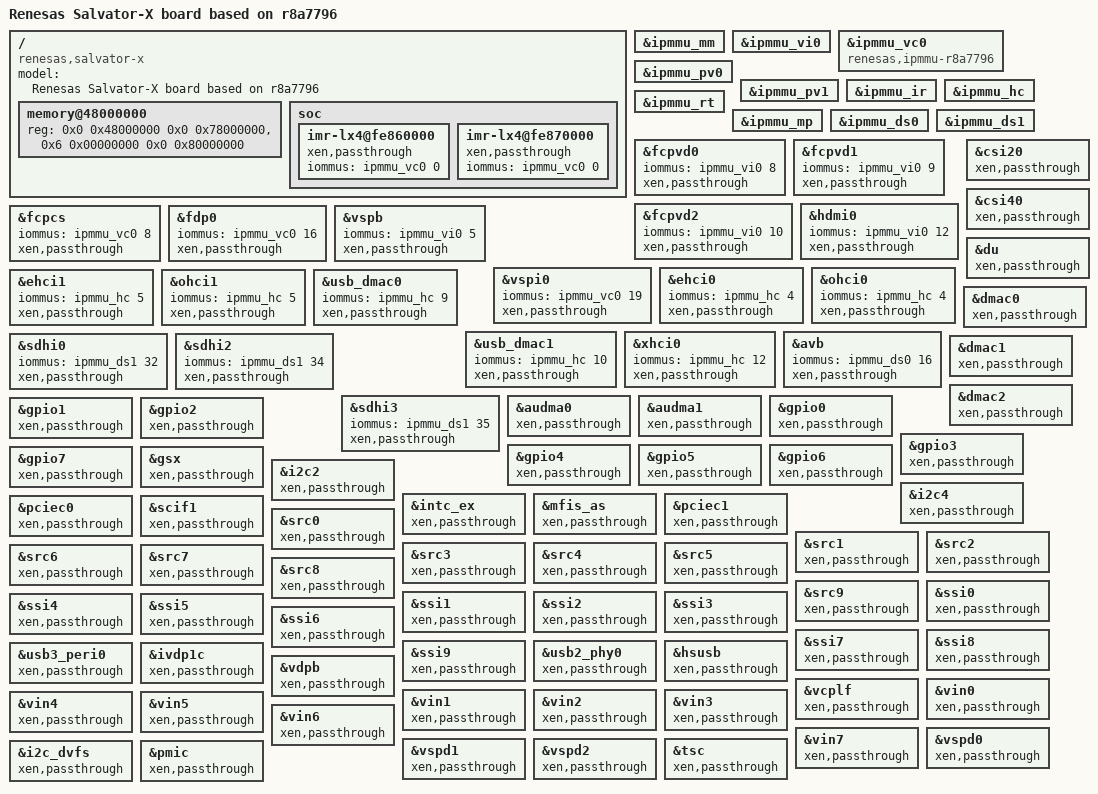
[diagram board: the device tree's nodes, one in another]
/*
 * Device Tree Source for the Salvator-X board
 *
 * Copyright (C) 2016 Renesas Electronics Corp.
 *
 * This file is licensed under the terms of the GNU General Public License
 * version 2.  This program is licensed "as is" without any warranty of any
 * kind, whether express or implied.
 */

#include "r8a7796-salvator-x.dts"
#include "xen-chosen.dtsi"

/ {
	model = "Renesas Salvator-X board based on r8a7796";
	compatible = "renesas,salvator-x", "renesas,r8a7796";

	memory@48000000 {
		device_type = "memory";
		/* first 128MB is reserved for secure area. */
		reg = <0x0 0x48000000 0x0 0x78000000>,
		      <0x6 0x00000000 0x0 0x80000000>;
	};

	/delete-node/memory@600000000;
	/delete-node/reserved-memory;

	/delete-node/mmngr;
	/delete-node/mmngrbuf;

	/*
	 * When creating DT for the guest domain Xen inserts only dummy CPU nodes.
	 * And the number of these inserted CPU nodes is equal to the number of
	 * vCPUs assigned to this domain. All CPU properties which original DT has,
	 * such as OPP, clock, regulator, etc are not passed to the guest’s DT.
	 *
	 * Example of guest vCPU node:
	 *
	 * cpu@0 {
	 *     device_type = "cpu";
	 *     compatible = "arm,armv8";
	 *     enable-method = "psci";
	 *     reg = <0x0>;
	 * };
	 *
	 * This results in the fact that all features expecting a57_x or a53_x
	 * CPU nodes to be present get broken. This is why we have to explicitly
	 * remove the following.
	 */
	/delete-node/thermal-zones;
	/delete-node/pmu_a57;
	/delete-node/pmu_a53;
};

/delete-node/&adsp;


/* ============================ Enabled IPMMUs ===============================*/
&ipmmu_mm {
	status = "okay";
};

&ipmmu_vi0 {
	status = "okay";
};

&ipmmu_vc0 {
	compatible = "renesas,ipmmu-r8a7796";
	status = "okay";
};

&ipmmu_pv0 {
	status = "okay";
};

&ipmmu_pv1 {
	status = "okay";
};

&ipmmu_ir {
};

&ipmmu_hc {
	status = "okay";
};

&ipmmu_rt {
};

&ipmmu_mp {
	status = "okay";
};

&ipmmu_ds0 {
	status = "okay";
};

&ipmmu_ds1 {
	status = "okay";
};

/*=========================== Bus masters linked to IPMMUS ===================*/

&fcpvd0 {
	iommus = <&ipmmu_vi0 8>;
};

&fcpvd1 {
	iommus = <&ipmmu_vi0 9>;
};

&fcpvd2 {
	iommus = <&ipmmu_vi0 10>;
};

&hdmi0 {
	iommus = <&ipmmu_vi0 12>;
};

&fcpcs {
	iommus = <&ipmmu_vc0 8>;
};

&fdp0 {
	iommus = <&ipmmu_vc0 16>;
};

&vspb {
	iommus = <&ipmmu_vi0 5>;
};

&vspi0 {
	iommus = <&ipmmu_vc0 19>;
};

/ {
	soc {
		imr-lx4@fe860000 {
			xen,passthrough;
			iommus = <&ipmmu_vc0 0>;
		};

		imr-lx4@fe870000 {
			xen,passthrough;
			iommus = <&ipmmu_vc0 0>;
		};
	};
};

&ehci0 {
	iommus = <&ipmmu_hc 4>;
};

&ohci0 {
	iommus = <&ipmmu_hc 4>;
};

&ehci1 {
	iommus = <&ipmmu_hc 5>;
};

&ohci1 {
	iommus = <&ipmmu_hc 5>;
};

&usb_dmac0 {
	iommus = <&ipmmu_hc 9>;
};

&usb_dmac1 {
	iommus = <&ipmmu_hc 10>;
};

&xhci0 {
	iommus = <&ipmmu_hc 12>;
};

&avb {
	iommus = <&ipmmu_ds0 16>;
};

&sdhi0 {
	iommus = <&ipmmu_ds1 32>;
};

&sdhi2 {
	iommus = <&ipmmu_ds1 34>;
};

&sdhi3 {
	iommus = <&ipmmu_ds1 35>;
};

/* ============================ Xen pass through section =====================*/

&csi20			{ xen,passthrough; };
&csi40			{ xen,passthrough; };
&du			{ xen,passthrough; };
&usb_dmac0		{ xen,passthrough; };
&usb_dmac1		{ xen,passthrough; };
&dmac0			{ xen,passthrough; };
&dmac1			{ xen,passthrough; };
&dmac2			{ xen,passthrough; };
&audma0			{ xen,passthrough; };
&audma1			{ xen,passthrough; };
&avb			{ xen,passthrough; };
&fdp0			{ xen,passthrough; };
&gpio0			{ xen,passthrough; };
&gpio1			{ xen,passthrough; };
&gpio2			{ xen,passthrough; };
&gpio3			{ xen,passthrough; };
&gpio4			{ xen,passthrough; };
&gpio5			{ xen,passthrough; };
&gpio6			{ xen,passthrough; };
&gpio7			{ xen,passthrough; };
&gsx			{ xen,passthrough; };
&hdmi0			{ xen,passthrough; };
&i2c2			{ xen,passthrough; };
&i2c4			{ xen,passthrough; };
&intc_ex		{ xen,passthrough; };
&mfis_as		{ xen,passthrough; };
&pciec1			{ xen,passthrough; };
&pciec0			{ xen,passthrough; };
&sdhi0			{ xen,passthrough; };
&sdhi2			{ xen,passthrough; };
&sdhi3			{ xen,passthrough; };
&scif1			{ xen,passthrough; };
&src0			{ xen,passthrough; };
&src1			{ xen,passthrough; };
&src2			{ xen,passthrough; };
&src3			{ xen,passthrough; };
&src4			{ xen,passthrough; };
&src5			{ xen,passthrough; };
&src6			{ xen,passthrough; };
&src7			{ xen,passthrough; };
&src8			{ xen,passthrough; };
&src9			{ xen,passthrough; };
&ssi0			{ xen,passthrough; };
&ssi1			{ xen,passthrough; };
&ssi2			{ xen,passthrough; };
&ssi3			{ xen,passthrough; };
&ssi4			{ xen,passthrough; };
&ssi5			{ xen,passthrough; };
&ssi6			{ xen,passthrough; };
&ssi7			{ xen,passthrough; };
&ssi8			{ xen,passthrough; };
&ssi9			{ xen,passthrough; };
&usb2_phy0		{ xen,passthrough; };
&hsusb			{ xen,passthrough; };
&xhci0			{ xen,passthrough; };
&usb3_peri0		{ xen,passthrough; };
&ohci0			{ xen,passthrough; };
&ehci0			{ xen,passthrough; };
&ohci1			{ xen,passthrough; };
&ehci1			{ xen,passthrough; };
&ivdp1c			{ xen,passthrough; };
&vdpb			{ xen,passthrough; };
&vcplf			{ xen,passthrough; };
&vin0			{ xen,passthrough; };
&vin1			{ xen,passthrough; };
&vin2			{ xen,passthrough; };
&vin3			{ xen,passthrough; };
&vin4			{ xen,passthrough; };
&vin5			{ xen,passthrough; };
&vin6			{ xen,passthrough; };
&vin7			{ xen,passthrough; };
&vspd0			{ xen,passthrough; };
&vspd1			{ xen,passthrough; };
&vspd2			{ xen,passthrough; };
&vspb			{ xen,passthrough; };
&vspi0			{ xen,passthrough; };

&fcpvd0			{ xen,passthrough; };
&fcpvd1			{ xen,passthrough; };
&fcpvd2			{ xen,passthrough; };
&fcpcs			{ xen,passthrough; };
&tsc			{ xen,passthrough; };
&i2c_dvfs		{ xen,passthrough; };
&pmic			{ xen,passthrough; };

